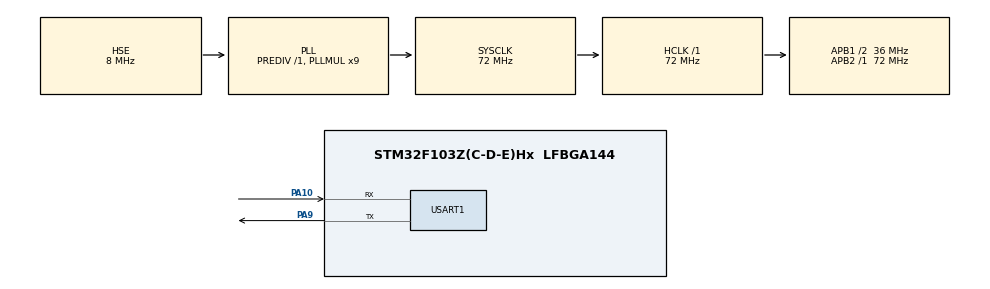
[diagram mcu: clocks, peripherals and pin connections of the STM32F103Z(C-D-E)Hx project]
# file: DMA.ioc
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Dma.Request0=USART1_RX
Dma.Request1=USART1_TX
Dma.USART1_RX.0.Direction=DMA_PERIPH_TO_MEMORY
Dma.USART1_RX.0.Instance=DMA1_Channel5
Dma.USART1_RX.0.MemDataAlignment=DMA_MDATAALIGN_BYTE
Dma.USART1_RX.0.MemInc=DMA_MINC_ENABLE
Dma.USART1_RX.0.Mode=DMA_NORMAL
Dma.USART1_RX.0.PeriphDataAlignment=DMA_PDATAALIGN_BYTE
Dma.USART1_RX.0.PeriphInc=DMA_PINC_DISABLE
Dma.USART1_RX.0.Priority=DMA_PRIORITY_HIGH
Dma.USART1_TX.1.Direction=DMA_MEMORY_TO_PERIPH
Dma.USART1_TX.1.Instance=DMA1_Channel4
Dma.USART1_TX.1.MemDataAlignment=DMA_MDATAALIGN_BYTE
Dma.USART1_TX.1.MemInc=DMA_MINC_ENABLE
Dma.USART1_TX.1.Mode=DMA_NORMAL
Dma.USART1_TX.1.PeriphDataAlignment=DMA_PDATAALIGN_BYTE
Dma.USART1_TX.1.PeriphInc=DMA_PINC_DISABLE
Dma.USART1_TX.1.Priority=DMA_PRIORITY_MEDIUM
Mcu.Family=STM32F1
Mcu.Name=STM32F103Z(C-D-E)Hx
Mcu.Package=LFBGA144
NVIC.DMA1_Channel4_IRQn=true\:2\:0\:true
NVIC.DMA1_Channel5_IRQn=true\:2\:0\:true
NVIC.PriorityGroup=NVIC_PRIORITYGROUP_4
NVIC.USART1_IRQn=true\:1\:0\:true
OSC_IN.Mode=HSE-External-Oscillator
OSC_IN.Signal=RCC_OSC_IN
OSC_OUT.Mode=HSE-External-Oscillator
OSC_OUT.Signal=RCC_OSC_OUT
PA10.Mode=Asynchronous
PA10.Signal=USART1_RX
PA13.Mode=JTAG_5_pin
PA13.Signal=SYS_JTMS-SWDIO
PA14.Mode=JTAG_5_pin
PA14.Signal=SYS_JTCK-SWCLK
PA15.Mode=JTAG_5_pin
PA15.Signal=SYS_JTDI
PA9.Mode=Asynchronous
PA9.Signal=USART1_TX
PB3.Mode=JTAG_5_pin
PB3.Signal=SYS_JTDO-TRACESWO
PB4.Mode=JTAG_5_pin
PB4.Signal=SYS_NJTRST
ProjectManager.TargetToolchain=MDK-ARM V5
RCC.AHBFreq_Value=72000000
RCC.APB1CLKDivider=RCC_HCLK_DIV2
RCC.APB1Freq_Value=36000000
RCC.APB1TimFreq_Value=72000000
RCC.APB2Freq_Value=72000000
RCC.APB2TimFreq_Value=72000000
RCC.HCLKFreq_Value=72000000
RCC.HSIState=RCC_HSI_ON
RCC.PLLMUL=RCC_PLL_MUL9
RCC.PLLSourceVirtual=RCC_PLLSOURCE_HSE
RCC.SYSCLKFreq_VALUE=72000000
RCC.SYSCLKSource=RCC_SYSCLKSOURCE_PLLCLK
RCC.USBFreq_Value=72000000
board=DMA

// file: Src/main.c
/**
  ******************************************************************************
  * File Name          : main.c
  * Description        : Main program body
  ******************************************************************************
  *
  * COPYRIGHT(c) 2016 STMicroelectronics
  *
  * Redistribution and use in source and binary forms, with or without modification,
  * are permitted provided that the following conditions are met:
  *   1. Redistributions of source code must retain the above copyright notice,
  *      this list of conditions and the following disclaimer.
  *   2. Redistributions in binary form must reproduce the above copyright notice,
  *      this list of conditions and the following disclaimer in the documentation
  *      and/or other materials provided with the distribution.
  *   3. Neither the name of STMicroelectronics nor the names of its contributors
  *      may be used to endorse or promote products derived from this software
  *      without specific prior written permission.
  *
  * THIS SOFTWARE IS PROVIDED BY THE COPYRIGHT HOLDERS AND CONTRIBUTORS "AS IS"
  * AND ANY EXPRESS OR IMPLIED WARRANTIES, INCLUDING, BUT NOT LIMITED TO, THE
  * IMPLIED WARRANTIES OF MERCHANTABILITY AND FITNESS FOR A PARTICULAR PURPOSE ARE
  * DISCLAIMED. IN NO EVENT SHALL THE COPYRIGHT HOLDER OR CONTRIBUTORS BE LIABLE
  * FOR ANY DIRECT, INDIRECT, INCIDENTAL, SPECIAL, EXEMPLARY, OR CONSEQUENTIAL
  * DAMAGES (INCLUDING, BUT NOT LIMITED TO, PROCUREMENT OF SUBSTITUTE GOODS OR
  * SERVICES; LOSS OF USE, DATA, OR PROFITS; OR BUSINESS INTERRUPTION) HOWEVER
  * CAUSED AND ON ANY THEORY OF LIABILITY, WHETHER IN CONTRACT, STRICT LIABILITY,
  * OR TORT (INCLUDING NEGLIGENCE OR OTHERWISE) ARISING IN ANY WAY OUT OF THE USE
  * OF THIS SOFTWARE, EVEN IF ADVISED OF THE POSSIBILITY OF SUCH DAMAGE.
  *
  ******************************************************************************
  */
#include "stm32f1xx_hal.h"

/* USER CODE BEGIN Includes */
#include "UART1.h"
/* USER CODE END Includes */

UART_HandleTypeDef huart1;
DMA_HandleTypeDef hdma_usart1_rx;
DMA_HandleTypeDef hdma_usart1_tx;

/* USER CODE BEGIN PV */
/* Private variables ---------------------------------------------------------*/

/* USER CODE END PV */

void SystemClock_Config(void);
static void MX_GPIO_Init(void);
static void MX_DMA_Init(void);
static void MX_USART1_UART_Init(void);

/* USER CODE BEGIN PFP */
/* Private function prototypes -----------------------------------------------*/

/* USER CODE END PFP */

int main(void)
{

  /* MCU Configuration----------------------------------------------------------*/

  /* Reset of all peripherals, Initializes the Flash interface and the Systick. */
  HAL_Init();

  /* Configure the system clock */
  SystemClock_Config();

  /* Initialize all configured peripherals */
  MX_GPIO_Init();
  MX_DMA_Init();
  MX_USART1_UART_Init();

  /* USER CODE BEGIN 2 */
	__HAL_UART_ENABLE_IT(&huart1, UART_IT_IDLE);    //开启空闲中断
  HAL_UART_Receive_DMA (&huart1, RxBuff, 100);    //开启DMA接收，100为最大长度
  /* USER CODE END 2 */

  /* Infinite loop */
  while (1)
  {

  /* USER CODE BEGIN 3 */
		UART1_Send_Date();
  }
  /* USER CODE END 3 */

}

/** System Clock Configuration
*/
void SystemClock_Config(void)
{

  RCC_OscInitTypeDef RCC_OscInitStruct;
  RCC_ClkInitTypeDef RCC_ClkInitStruct;

  RCC_OscInitStruct.OscillatorType = RCC_OSCILLATORTYPE_HSE;
  RCC_OscInitStruct.HSEState = RCC_HSE_ON;
  RCC_OscInitStruct.HSEPredivValue = RCC_HSE_PREDIV_DIV1;
  RCC_OscInitStruct.PLL.PLLState = RCC_PLL_ON;
  RCC_OscInitStruct.PLL.PLLSource = RCC_PLLSOURCE_HSE;
  RCC_OscInitStruct.PLL.PLLMUL = RCC_PLL_MUL9;
  HAL_RCC_OscConfig(&RCC_OscInitStruct);

  RCC_ClkInitStruct.ClockType = RCC_CLOCKTYPE_SYSCLK|RCC_CLOCKTYPE_PCLK1;
  RCC_ClkInitStruct.SYSCLKSource = RCC_SYSCLKSOURCE_PLLCLK;
  RCC_ClkInitStruct.AHBCLKDivider = RCC_SYSCLK_DIV1;
  RCC_ClkInitStruct.APB1CLKDivider = RCC_HCLK_DIV2;
  RCC_ClkInitStruct.APB2CLKDivider = RCC_HCLK_DIV1;
  HAL_RCC_ClockConfig(&RCC_ClkInitStruct, FLASH_LATENCY_2);

  HAL_SYSTICK_Config(HAL_RCC_GetHCLKFreq()/1000);

  HAL_SYSTICK_CLKSourceConfig(SYSTICK_CLKSOURCE_HCLK);

  /* SysTick_IRQn interrupt configuration */
  HAL_NVIC_SetPriority(SysTick_IRQn, 0, 0);
}

/* USART1 init function */
void MX_USART1_UART_Init(void)
{

  huart1.Instance = USART1;
  huart1.Init.BaudRate = 115200;
  huart1.Init.WordLength = UART_WORDLENGTH_8B;
  huart1.Init.StopBits = UART_STOPBITS_1;
  huart1.Init.Parity = UART_PARITY_NONE;
  huart1.Init.Mode = UART_MODE_TX_RX;
  huart1.Init.HwFlowCtl = UART_HWCONTROL_NONE;
  huart1.Init.OverSampling = UART_OVERSAMPLING_16;
  HAL_UART_Init(&huart1);

}

void MX_DMA_Init(void)
{
  /* DMA controller clock enable */
  __HAL_RCC_DMA1_CLK_ENABLE();

  /* DMA interrupt init */
  HAL_NVIC_SetPriority(DMA1_Channel4_IRQn, 2, 0);
  HAL_NVIC_EnableIRQ(DMA1_Channel4_IRQn);
  HAL_NVIC_SetPriority(DMA1_Channel5_IRQn, 2, 0);
  HAL_NVIC_EnableIRQ(DMA1_Channel5_IRQn);

}

/** Configure pins as
        * Analog
        * Input
        * Output
        * EVENT_OUT
        * EXTI
*/
void MX_GPIO_Init(void)
{

  /* GPIO Ports Clock Enable */
  __GPIOB_CLK_ENABLE();
  __GPIOA_CLK_ENABLE();

}

/************************ (C) COPYRIGHT STMicroelectronics *****END OF FILE****/
